AUTOSAR XML (schema 4-2-2)
package /Components
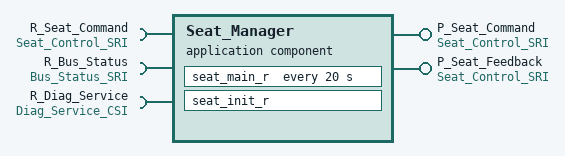
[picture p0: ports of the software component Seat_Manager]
  application sw component type Seat_Manager
    provide port P_Seat_Command: provided-interface=Seat_Control_SRI
    provide port P_Seat_Feedback: provided-interface=Seat_Control_SRI
    require port R_Seat_Command: required-interface=Seat_Control_SRI
    require port R_Bus_Status: required-interface=Bus_Status_SRI
    require port R_Diag_Service: required-interface=Diag_Service_CSI
    behavior Seat_Manager_InternalBehavior
      init event Seat_Init: start-on-event=seat_init_r
      timing event Seat_Main_Cycle: start-on-event=seat_main_r, period=20
      runnable seat_init_r: symbol=Seat_Init_R
        data-receive-point-by-arguments:
          access rx_bus_online_init: accessed-variable=R_Bus_Status.bus_online
        data-send-points:
          access tx_initial_seat_position_feedback: accessed-variable=P_Seat_Feedback.seat_position_feedback
          access tx_initial_seat_heater_status: accessed-variable=P_Seat_Feedback.seat_heater_status
        parameter access param_read_bus_error_count_init: accessed-parameter=R_Bus_Status.bus_error_count
        parameter access param_read_bus_load_init: accessed-parameter=R_Bus_Status.bus_load
        sync call scp_get_update_status_init: operation=R_Diag_Service.GetUpdateStatus, timeout=1000
      runnable seat_main_r: minimum-start-interval=20, symbol=Seat_Main_R
        data-receive-point-by-arguments:
          5 x access:
            rx_seat_position_cmd: accessed-variable=R_Seat_Command.seat_position_cmd
            rx_seat_heater_cmd: accessed-variable=R_Seat_Command.seat_heater_cmd
            rx_bus_online: accessed-variable=R_Bus_Status.bus_online
            rx_bus_error_count: accessed-variable=R_Bus_Status.bus_error_count
            rx_bus_load: accessed-variable=R_Bus_Status.bus_load
        data-send-points:
          4 x access:
            tx_seat_position_cmd: accessed-variable=P_Seat_Command.seat_position_cmd
            tx_seat_heater_cmd: accessed-variable=P_Seat_Command.seat_heater_cmd
            tx_seat_position_feedback: accessed-variable=P_Seat_Feedback.seat_position_feedback
            tx_seat_heater_status: accessed-variable=P_Seat_Feedback.seat_heater_status
        parameter access param_read_bus_load_main: accessed-parameter=R_Bus_Status.bus_load
        sync call scp_get_update_status_main: operation=R_Diag_Service.GetUpdateStatus, timeout=2000
